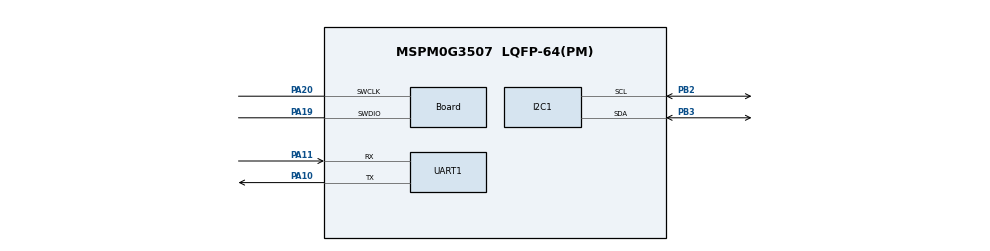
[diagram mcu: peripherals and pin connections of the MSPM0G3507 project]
// @cliArgs --device "MSPM0G350X" --package "LQFP-64(PM)" --part "Default"
// @v2CliArgs --device "MSPM0G3507" --package "LQFP-64(PM)"
// @cliArgs --board /ti/boards/LP_MSPM0G3507 --rtos nortos

/**
 * Import the modules used in this configuration.
 */
const Board         = scripting.addModule("/ti/driverlib/Board");
const I2C           = scripting.addModule("/ti/driverlib/I2C", {}, false);
const I2C1          = I2C.addInstance();
const MATHACL       = scripting.addModule("/ti/driverlib/MATHACL");
const SYSCTL        = scripting.addModule("/ti/driverlib/SYSCTL");
const TIMER         = scripting.addModule("/ti/driverlib/TIMER", {}, false);
const TIMER1        = TIMER.addInstance();
const UART          = scripting.addModule("/ti/driverlib/UART", {}, false);
const UART1         = UART.addInstance();
const ProjectConfig = scripting.addModule("/ti/project_config/ProjectConfig");

/**
 * Write custom configuration values to the imported modules.
 */
Board.peripheral.$assign          = "DEBUGSS";
Board.peripheral.swclkPin.$assign = "PA20";
Board.peripheral.swdioPin.$assign = "PA19";

I2C1.$name                     = "I2C_0";
I2C1.basicEnableController     = true;
I2C1.advAnalogGlitchFilter     = "DISABLED";
I2C1.advControllerTXFIFOTRIG   = "BYTES_1";
I2C1.peripheral.$assign        = "I2C1";
I2C1.peripheral.sdaPin.$assign = "PB3";
I2C1.peripheral.sclPin.$assign = "PB2";

SYSCTL.peripheral.$assign = "SYSCTL";

TIMER1.timerClkSrc        = "LFCLK";
TIMER1.timerMode          = "PERIODIC";
TIMER1.timerPeriod        = "1 s";
TIMER1.$name              = "TIMER";
TIMER1.interrupts         = ["ZERO"];
TIMER1.timerClkDiv        = 8;
TIMER1.peripheral.$assign = "TIMG0";

UART1.targetBaudRate                   = 256000;
UART1.$name                            = "UART_SYS";
UART1.peripheral.$assign               = "UART0";
UART1.peripheral.rxPin.$assign         = "PA11";
UART1.peripheral.txPin.$assign         = "PA10";
UART1.txPinConfig.enableConfig         = true;
UART1.txPinConfig.internalResistor     = "PULL_UP";
UART1.rxPinConfig.enableConfig         = true;
UART1.rxPinConfig.internalResistor     = "PULL_UP";

ProjectConfig.genLibIQ        = true;
ProjectConfig.genLibIQVersion = "MATHACL";
ProjectConfig.genLibGaugeL2        = true;
ProjectConfig.genLibGaugeL2Version = "MATHACL";
